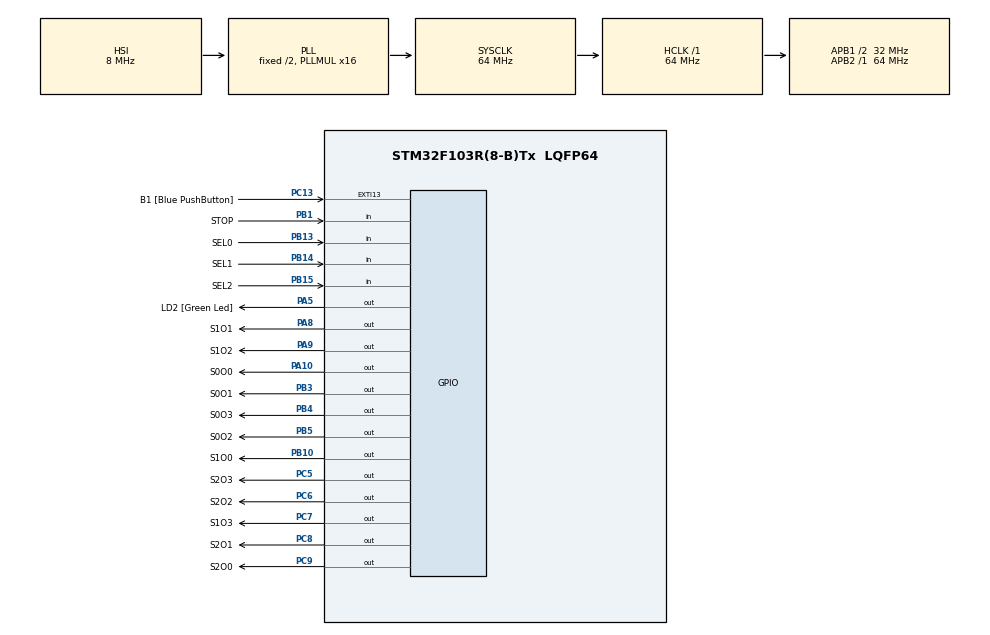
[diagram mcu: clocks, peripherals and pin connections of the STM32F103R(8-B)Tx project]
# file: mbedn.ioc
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Mcu.Family=STM32F1
Mcu.Name=STM32F103R(8-B)Tx
Mcu.Package=LQFP64
NVIC.EXTI15_10_IRQn=true\:0\:0\:false\:false\:true
NVIC.PriorityGroup=NVIC_PRIORITYGROUP_4
NVIC.TIM2_IRQn=true\:0\:0\:false\:false\:true
PA10.GPIO_Label=S0O0
PA10.Signal=GPIO_Output
PA13.GPIO_Label=TMS
PA13.Mode=Serial_Wire
PA13.Signal=SYS_JTMS-SWDIO
PA14.GPIO_Label=TCK
PA14.Mode=Serial_Wire
PA14.Signal=SYS_JTCK-SWCLK
PA5.GPIO_Label=LD2 [Green Led]
PA5.GPIO_ModeDefaultOutputPP=GPIO_MODE_OUTPUT_PP
PA5.GPIO_PuPd=GPIO_NOPULL
PA5.GPIO_Speed=GPIO_SPEED_FREQ_LOW
PA5.Signal=GPIO_Output
PA8.GPIO_Label=S1O1
PA8.Signal=GPIO_Output
PA9.GPIO_Label=S1O2
PA9.Signal=GPIO_Output
PB1.GPIO_Label=STOP
PB1.GPIO_PuPd=GPIO_PULLUP
PB1.Signal=GPIO_Input
PB10.GPIO_Label=S1O0
PB10.Signal=GPIO_Output
PB13.GPIO_Label=SEL0
PB13.GPIO_PuPd=GPIO_PULLUP
PB13.Signal=GPIO_Input
PB14.GPIO_Label=SEL1
PB14.GPIO_PuPd=GPIO_PULLUP
PB14.Signal=GPIO_Input
PB15.GPIO_Label=SEL2
PB15.GPIO_PuPd=GPIO_PULLUP
PB15.Signal=GPIO_Input
PB3.GPIO_Label=S0O1
PB3.Signal=GPIO_Output
PB4.GPIO_Label=S0O3
PB4.Signal=GPIO_Output
PB5.GPIO_Label=S0O2
PB5.Signal=GPIO_Output
PC13-TAMPER-RTC.GPIO_Label=B1 [Blue PushButton]
PC13-TAMPER-RTC.GPIO_ModeDefaultEXTI=GPIO_MODE_IT_RISING
PC13-TAMPER-RTC.GPIO_PuPd=GPIO_NOPULL
PC13-TAMPER-RTC.Signal=GPXTI13
PC14-OSC32_IN.Signal=RCC_OSC32_IN
PC15-OSC32_OUT.Signal=RCC_OSC32_OUT
PC5.GPIO_Label=S2O3
PC5.Signal=GPIO_Output
PC6.GPIO_Label=S2O2
PC6.Signal=GPIO_Output
PC7.GPIO_Label=S1O3
PC7.Signal=GPIO_Output
PC8.GPIO_Label=S2O1
PC8.Signal=GPIO_Output
PC9.GPIO_Label=S2O0
PC9.Signal=GPIO_Output
PD0-OSC_IN.Signal=RCC_OSC_IN
PD1-OSC_OUT.Signal=RCC_OSC_OUT
ProjectManager.HeapSize=0x200
ProjectManager.StackSize=0x400
ProjectManager.TargetToolchain=SW4STM32
RCC.AHBFreq_Value=64000000
RCC.APB1CLKDivider=RCC_HCLK_DIV2
RCC.APB1Freq_Value=32000000
RCC.APB1TimFreq_Value=64000000
RCC.APB2Freq_Value=64000000
RCC.APB2TimFreq_Value=64000000
RCC.HCLKFreq_Value=64000000
RCC.PLLMUL=RCC_PLL_MUL16
RCC.SYSCLKFreq_VALUE=64000000
RCC.SYSCLKSource=RCC_SYSCLKSOURCE_PLLCLK
RCC.USBFreq_Value=64000000
TIM2.Period=100
TIM2.Prescaler=640
VP_TIM2_VS_ClockSourceINT.Mode=Internal
board=NUCLEO-F103RB

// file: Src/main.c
/**
  ******************************************************************************
  * File Name          : main.c
  * Description        : Main program body
  ******************************************************************************
  *
  * COPYRIGHT(c) 2017 STMicroelectronics
  *
  * Redistribution and use in source and binary forms, with or without modification,
  * are permitted provided that the following conditions are met:
  *   1. Redistributions of source code must retain the above copyright notice,
  *      this list of conditions and the following disclaimer.
  *   2. Redistributions in binary form must reproduce the above copyright notice,
  *      this list of conditions and the following disclaimer in the documentation
  *      and/or other materials provided with the distribution.
  *   3. Neither the name of STMicroelectronics nor the names of its contributors
  *      may be used to endorse or promote products derived from this software
  *      without specific prior written permission.
  *
  * THIS SOFTWARE IS PROVIDED BY THE COPYRIGHT HOLDERS AND CONTRIBUTORS "AS IS"
  * AND ANY EXPRESS OR IMPLIED WARRANTIES, INCLUDING, BUT NOT LIMITED TO, THE
  * IMPLIED WARRANTIES OF MERCHANTABILITY AND FITNESS FOR A PARTICULAR PURPOSE ARE
  * DISCLAIMED. IN NO EVENT SHALL THE COPYRIGHT HOLDER OR CONTRIBUTORS BE LIABLE
  * FOR ANY DIRECT, INDIRECT, INCIDENTAL, SPECIAL, EXEMPLARY, OR CONSEQUENTIAL
  * DAMAGES (INCLUDING, BUT NOT LIMITED TO, PROCUREMENT OF SUBSTITUTE GOODS OR
  * SERVICES; LOSS OF USE, DATA, OR PROFITS; OR BUSINESS INTERRUPTION) HOWEVER
  * CAUSED AND ON ANY THEORY OF LIABILITY, WHETHER IN CONTRACT, STRICT LIABILITY,
  * OR TORT (INCLUDING NEGLIGENCE OR OTHERWISE) ARISING IN ANY WAY OUT OF THE USE
  * OF THIS SOFTWARE, EVEN IF ADVISED OF THE POSSIBILITY OF SUCH DAMAGE.
  *
  ******************************************************************************
  */
#include "main.h"
#include "stm32f1xx_hal.h"

/* USER CODE BEGIN Includes */

#include "logik.h"

/* USER CODE END Includes */

TIM_HandleTypeDef htim2;

/* USER CODE BEGIN PV */
/* Private variables ---------------------------------------------------------*/

/* USER CODE END PV */

void SystemClock_Config(void);
void Error_Handler(void);
static void MX_GPIO_Init(void);
static void MX_TIM2_Init(void);

/* USER CODE BEGIN PFP */
/* Private function prototypes -----------------------------------------------*/

/* USER CODE END PFP */

int main(void)
{

  /* MCU Configuration----------------------------------------------------------*/

  /* Reset of all peripherals, Initializes the Flash interface and the Systick. */
  HAL_Init();

  /* Configure the system clock */
  SystemClock_Config();

  /* Initialize all configured peripherals */
  MX_GPIO_Init();
  MX_TIM2_Init();

  /* USER CODE BEGIN 2 */

	HAL_TIM_Base_Start_IT(&htim2);							//start timer 2

	init_outputs_configuration();							//signals setup

	disable_signals();										//signals stopped

	init_inputs_configuration();							//inputs setup

	init_info_configuration();								//info LED setup

  /* USER CODE END 2 */

  /* Infinite loop */
  while (1)
  {

  /* USER CODE BEGIN 3 */

	  logik_main_loop();									//main logik

  }
  /* USER CODE END 3 */

}

/** System Clock Configuration
*/
void SystemClock_Config(void)
{

  RCC_OscInitTypeDef RCC_OscInitStruct;
  RCC_ClkInitTypeDef RCC_ClkInitStruct;

    /**Initializes the CPU, AHB and APB busses clocks
    */
  RCC_OscInitStruct.OscillatorType = RCC_OSCILLATORTYPE_HSI;
  RCC_OscInitStruct.HSIState = RCC_HSI_ON;
  RCC_OscInitStruct.HSICalibrationValue = 16;
  RCC_OscInitStruct.PLL.PLLState = RCC_PLL_ON;
  RCC_OscInitStruct.PLL.PLLSource = RCC_PLLSOURCE_HSI_DIV2;
  RCC_OscInitStruct.PLL.PLLMUL = RCC_PLL_MUL16;
  if (HAL_RCC_OscConfig(&RCC_OscInitStruct) != HAL_OK)
  {
    Error_Handler();
  }

    /**Initializes the CPU, AHB and APB busses clocks
    */
  RCC_ClkInitStruct.ClockType = RCC_CLOCKTYPE_HCLK|RCC_CLOCKTYPE_SYSCLK
                              |RCC_CLOCKTYPE_PCLK1|RCC_CLOCKTYPE_PCLK2;
  RCC_ClkInitStruct.SYSCLKSource = RCC_SYSCLKSOURCE_PLLCLK;
  RCC_ClkInitStruct.AHBCLKDivider = RCC_SYSCLK_DIV1;
  RCC_ClkInitStruct.APB1CLKDivider = RCC_HCLK_DIV2;
  RCC_ClkInitStruct.APB2CLKDivider = RCC_HCLK_DIV1;

  if (HAL_RCC_ClockConfig(&RCC_ClkInitStruct, FLASH_LATENCY_2) != HAL_OK)
  {
    Error_Handler();
  }

    /**Configure the Systick interrupt time
    */
  HAL_SYSTICK_Config(HAL_RCC_GetHCLKFreq()/1000);

    /**Configure the Systick
    */
  HAL_SYSTICK_CLKSourceConfig(SYSTICK_CLKSOURCE_HCLK);

  /* SysTick_IRQn interrupt configuration */
  HAL_NVIC_SetPriority(SysTick_IRQn, 0, 0);
}

/* TIM2 init function */
static void MX_TIM2_Init(void)
{

  TIM_ClockConfigTypeDef sClockSourceConfig;
  TIM_MasterConfigTypeDef sMasterConfig;

  htim2.Instance = TIM2;
  htim2.Init.Prescaler = 640;
  htim2.Init.CounterMode = TIM_COUNTERMODE_UP;
  htim2.Init.Period = 100;
  htim2.Init.ClockDivision = TIM_CLOCKDIVISION_DIV1;
  if (HAL_TIM_Base_Init(&htim2) != HAL_OK)
  {
    Error_Handler();
  }

  sClockSourceConfig.ClockSource = TIM_CLOCKSOURCE_INTERNAL;
  if (HAL_TIM_ConfigClockSource(&htim2, &sClockSourceConfig) != HAL_OK)
  {
    Error_Handler();
  }

  sMasterConfig.MasterOutputTrigger = TIM_TRGO_RESET;
  sMasterConfig.MasterSlaveMode = TIM_MASTERSLAVEMODE_DISABLE;
  if (HAL_TIMEx_MasterConfigSynchronization(&htim2, &sMasterConfig) != HAL_OK)
  {
    Error_Handler();
  }

}

/** Configure pins as
        * Analog
        * Input
        * Output
        * EVENT_OUT
        * EXTI
*/
static void MX_GPIO_Init(void)
{

  GPIO_InitTypeDef GPIO_InitStruct;

  /* GPIO Ports Clock Enable */
  __HAL_RCC_GPIOC_CLK_ENABLE();
  __HAL_RCC_GPIOD_CLK_ENABLE();
  __HAL_RCC_GPIOA_CLK_ENABLE();
  __HAL_RCC_GPIOB_CLK_ENABLE();

  /*Configure GPIO pin : B1_Pin */
  GPIO_InitStruct.Pin = B1_Pin;
  GPIO_InitStruct.Mode = GPIO_MODE_IT_RISING;
  GPIO_InitStruct.Pull = GPIO_NOPULL;
  HAL_GPIO_Init(B1_GPIO_Port, &GPIO_InitStruct);

  /*Configure GPIO pins : LD2_Pin S1O1_Pin S1O2_Pin S0O0_Pin */
  GPIO_InitStruct.Pin = LD2_Pin|S1O1_Pin|S1O2_Pin|S0O0_Pin;
  GPIO_InitStruct.Mode = GPIO_MODE_OUTPUT_PP;
  GPIO_InitStruct.Speed = GPIO_SPEED_FREQ_LOW;
  HAL_GPIO_Init(GPIOA, &GPIO_InitStruct);

  /*Configure GPIO pins : S2O3_Pin S2O2_Pin S1O3_Pin S2O1_Pin
                           S2O0_Pin */
  GPIO_InitStruct.Pin = S2O3_Pin|S2O2_Pin|S1O3_Pin|S2O1_Pin
                          |S2O0_Pin;
  GPIO_InitStruct.Mode = GPIO_MODE_OUTPUT_PP;
  GPIO_InitStruct.Speed = GPIO_SPEED_FREQ_LOW;
  HAL_GPIO_Init(GPIOC, &GPIO_InitStruct);

  /*Configure GPIO pins : STOP_Pin SEL0_Pin SEL1_Pin SEL2_Pin */
  GPIO_InitStruct.Pin = STOP_Pin|SEL0_Pin|SEL1_Pin|SEL2_Pin;
  GPIO_InitStruct.Mode = GPIO_MODE_INPUT;
  GPIO_InitStruct.Pull = GPIO_PULLUP;
  HAL_GPIO_Init(GPIOB, &GPIO_InitStruct);

  /*Configure GPIO pins : S1O0_Pin S0O1_Pin S0O3_Pin S0O2_Pin */
  GPIO_InitStruct.Pin = S1O0_Pin|S0O1_Pin|S0O3_Pin|S0O2_Pin;
  GPIO_InitStruct.Mode = GPIO_MODE_OUTPUT_PP;
  GPIO_InitStruct.Speed = GPIO_SPEED_FREQ_LOW;
  HAL_GPIO_Init(GPIOB, &GPIO_InitStruct);

  /*Configure GPIO pin Output Level */
  HAL_GPIO_WritePin(GPIOA, LD2_Pin|S1O1_Pin|S1O2_Pin|S0O0_Pin, GPIO_PIN_RESET);

  /*Configure GPIO pin Output Level */
  HAL_GPIO_WritePin(GPIOC, S2O3_Pin|S2O2_Pin|S1O3_Pin|S2O1_Pin
                          |S2O0_Pin, GPIO_PIN_RESET);

  /*Configure GPIO pin Output Level */
  HAL_GPIO_WritePin(GPIOB, S1O0_Pin|S0O1_Pin|S0O3_Pin|S0O2_Pin, GPIO_PIN_RESET);

  /* EXTI interrupt init*/
  HAL_NVIC_SetPriority(EXTI15_10_IRQn, 0, 0);
  HAL_NVIC_EnableIRQ(EXTI15_10_IRQn);

}

void Error_Handler(void)
{
  while(1)
  {
  }
}

/************************ (C) COPYRIGHT STMicroelectronics *****END OF FILE****/
